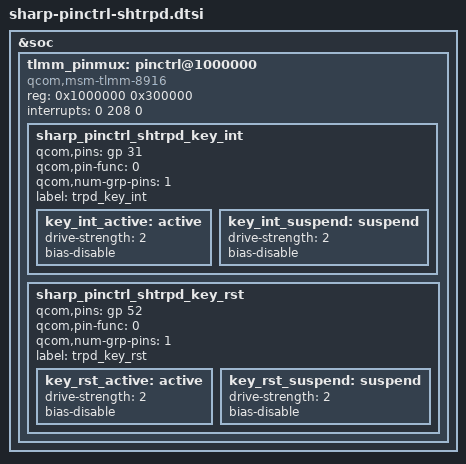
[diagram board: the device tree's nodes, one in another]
/* Copyright (c) 2013-2014, The Linux Foundation. All rights reserved.
 *
 * This program is free software; you can redistribute it and/or modify
 * it under the terms of the GNU General Public License version 2 and
 * only version 2 as published by the Free Software Foundation.
 *
 * This program is distributed in the hope that it will be useful,
 * but WITHOUT ANY WARRANTY; without even the implied warranty of
 * MERCHANTABILITY or FITNESS FOR A PARTICULAR PURPOSE.  See the
 * GNU General Public License for more details.
 */

&soc {
	tlmm_pinmux: pinctrl@1000000 {
		compatible = "qcom,msm-tlmm-8916";
		reg = <0x1000000 0x300000>;
		interrupts = <0 208 0>;
		/*****************************************/
		/*  pinctrl customize setting            */
		/*****************************************/
		sharp_pinctrl_shtrpd_key_int{
			qcom,pins = <&gp 31>;
			qcom,pin-func = <0>;
			qcom,num-grp-pins = <1>;
			label = "trpd_key_int";
			key_int_active: active {
				drive-strength = <2>;
				bias-disable;
			};
			key_int_suspend: suspend {
				drive-strength = <2>;
				bias-disable;
			};
		};
		sharp_pinctrl_shtrpd_key_rst{
			qcom,pins = <&gp 52>;
			qcom,pin-func = <0>;
			qcom,num-grp-pins = <1>;
			label = "trpd_key_rst";
			key_rst_active: active {
				drive-strength = <2>;
				bias-disable;
			};
			key_rst_suspend: suspend {
				drive-strength = <2>;
				bias-disable;
			};
		};
	};
};
